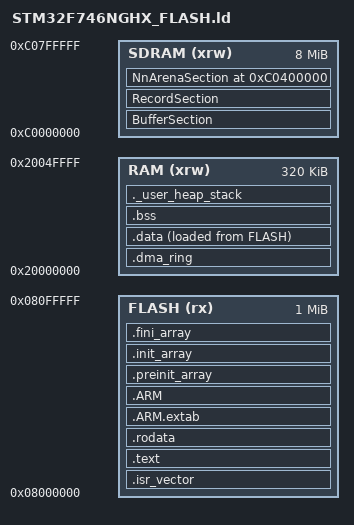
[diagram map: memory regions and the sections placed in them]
/*
******************************************************************************
**
**  File        : LinkerScript.ld
**
**  Author		: Auto-generated by STM32CubeIDE
**
**  Abstract    : Linker script for STM32F746NGHx Device from stm32f7 series
**                      1024Kbytes FLASH
**                      320Kbytes RAM
**
**                Set heap size, stack size and stack location according
**                to application requirements.
**
**                Set memory bank area and size if external memory is used.
**
**  Target      : STMicroelectronics STM32
**
**  Distribution: The file is distributed as is without any warranty
**                of any kind.
**
*****************************************************************************
** @attention
**
** <h2><center>&copy; COPYRIGHT(c) 2019 STMicroelectronics</center></h2>
**
** Redistribution and use in source and binary forms, with or without modification,
** are permitted provided that the following conditions are met:
**   1. Redistributions of source code must retain the above copyright notice,
**      this list of conditions and the following disclaimer.
**   2. Redistributions in binary form must reproduce the above copyright notice,
**      this list of conditions and the following disclaimer in the documentation
**      and/or other materials provided with the distribution.
**   3. Neither the name of STMicroelectronics nor the names of its contributors
**      may be used to endorse or promote products derived from this software
**      without specific prior written permission.
**
** THIS SOFTWARE IS PROVIDED BY THE COPYRIGHT HOLDERS AND CONTRIBUTORS "AS IS"
** AND ANY EXPRESS OR IMPLIED WARRANTIES, INCLUDING, BUT NOT LIMITED TO, THE
** IMPLIED WARRANTIES OF MERCHANTABILITY AND FITNESS FOR A PARTICULAR PURPOSE ARE
** DISCLAIMED. IN NO EVENT SHALL THE COPYRIGHT HOLDER OR CONTRIBUTORS BE LIABLE
** FOR ANY DIRECT, INDIRECT, INCIDENTAL, SPECIAL, EXEMPLARY, OR CONSEQUENTIAL
** DAMAGES (INCLUDING, BUT NOT LIMITED TO, PROCUREMENT OF SUBSTITUTE GOODS OR
** SERVICES; LOSS OF USE, DATA, OR PROFITS; OR BUSINESS INTERRUPTION) HOWEVER
** CAUSED AND ON ANY THEORY OF LIABILITY, WHETHER IN CONTRACT, STRICT LIABILITY,
** OR TORT (INCLUDING NEGLIGENCE OR OTHERWISE) ARISING IN ANY WAY OUT OF THE USE
** OF THIS SOFTWARE, EVEN IF ADVISED OF THE POSSIBILITY OF SUCH DAMAGE.
**
*****************************************************************************
*/

/* Entry Point */
ENTRY(Reset_Handler)

/* Highest address of the user mode stack */
_estack = ORIGIN(RAM) + LENGTH(RAM);	/* end of "RAM" Ram type memory */

_Min_Heap_Size = 0xa00 ;	/* required amount of heap  */
_Min_Stack_Size = 0xa00 ;	/* required amount of stack */

/* Memories definition */
MEMORY
{
  RAM     (xrw)  : ORIGIN = 0x20000000,  LENGTH = 320K
  FLASH   (rx)   : ORIGIN = 0x8000000,   LENGTH = 1024K
  SDRAM   (xrw)  : ORIGIN = 0xC0000000,  LENGTH = 8M
}

/* Sections */
SECTIONS
{
  /* The startup code into "FLASH" Rom type memory */
  .isr_vector :
  {
    . = ALIGN(4);
    KEEP(*(.isr_vector)) /* Startup code */
    . = ALIGN(4);
  } >FLASH

  /* The program code and other data into "FLASH" Rom type memory */
  .text :
  {
    . = ALIGN(4);
    *(.text)           /* .text sections (code) */
    *(.text*)          /* .text* sections (code) */
    *(.glue_7)         /* glue arm to thumb code */
    *(.glue_7t)        /* glue thumb to arm code */
    *(.eh_frame)

    KEEP (*(.init))
    KEEP (*(.fini))

    . = ALIGN(4);
    _etext = .;        /* define a global symbols at end of code */
  } >FLASH

  /* Constant data into "FLASH" Rom type memory */
  .rodata :
  {
    . = ALIGN(4);
    *(.rodata)         /* .rodata sections (constants, strings, etc.) */
    *(.rodata*)        /* .rodata* sections (constants, strings, etc.) */
    . = ALIGN(4);
  } >FLASH

  .ARM.extab   : {
    . = ALIGN(4);
    *(.ARM.extab* .gnu.linkonce.armextab.*)
    . = ALIGN(4);
  } >FLASH

  .ARM : {
    . = ALIGN(4);
    __exidx_start = .;
    *(.ARM.exidx*)
    __exidx_end = .;
    . = ALIGN(4);
  } >FLASH

  .preinit_array     :
  {
    . = ALIGN(4);
    PROVIDE_HIDDEN (__preinit_array_start = .);
    KEEP (*(.preinit_array*))
    PROVIDE_HIDDEN (__preinit_array_end = .);
    . = ALIGN(4);
  } >FLASH

  .init_array :
  {
    . = ALIGN(4);
    PROVIDE_HIDDEN (__init_array_start = .);
    KEEP (*(SORT(.init_array.*)))
    KEEP (*(.init_array*))
    PROVIDE_HIDDEN (__init_array_end = .);
    . = ALIGN(4);
  } >FLASH

  .fini_array :
  {
    . = ALIGN(4);
    PROVIDE_HIDDEN (__fini_array_start = .);
    KEEP (*(SORT(.fini_array.*)))
    KEEP (*(.fini_array*))
    PROVIDE_HIDDEN (__fini_array_end = .);
    . = ALIGN(4);
  } >FLASH

  /* Used by the startup to initialize data */
  _sidata = LOADADDR(.data);

  /* DMA ring of the event task: first thing in RAM, i.e. in the DTCM (0x20000000, 64 KB), which the core
     does not cache and the DMA reaches through the AHBS port */
  .dma_ring (NOLOAD) :
  {
    . = ALIGN(32);
    *(.dma_ring .dma_ring.*)
    . = ALIGN(32);
  } >RAM

  /* Initialized data sections into "RAM" Ram type memory */
  .data :
  {
    . = ALIGN(4);
    _sdata = .;        /* create a global symbol at data start */
    *(.data)           /* .data sections */
    *(.data*)          /* .data* sections */

    . = ALIGN(4);
    _edata = .;        /* define a global symbol at data end */

  } >RAM AT> FLASH

  /* Uninitialized data section into "RAM" Ram type memory */
  . = ALIGN(4);
  .bss :
  {
    /* This is used by the startup in order to initialize the .bss section */
    _sbss = .;         /* define a global symbol at bss start */
    __bss_start__ = _sbss;
    *(.bss)
    *(.bss*)
    *(COMMON)

    . = ALIGN(4);
    _ebss = .;         /* define a global symbol at bss end */
    __bss_end__ = _ebss;
  } >RAM

  /* User_heap_stack section, used to check that there is enough "RAM" Ram  type memory left */
  ._user_heap_stack :
  {
    . = ALIGN(8);
    PROVIDE ( end = . );
    PROVIDE ( _end = . );
    . = . + _Min_Heap_Size;
    . = . + _Min_Stack_Size;
    . = ALIGN(8);
  } >RAM

  /* Remove information from the compiler libraries */
  /DISCARD/ :
  {
    libc.a ( * )
    libm.a ( * )
    libgcc.a ( * )
  }

  .ARM.attributes 0 : { *(.ARM.attributes) }

  /* Frame buffers: lower 4 MB of SDRAM, device memory (not cached), shared with the LTDC and the DMA */
  BufferSection (NOLOAD) :
  {
    . = ALIGN(32);
    *(Display_Buffers Display_Buffers.*)
    . = ALIGN(32);
    *(Uncached_SDRAM Uncached_SDRAM.*)
    . = ALIGN(32);
  } >SDRAM

  /* Event recording buffer (tools/record.py): also not cached, so a debugger dump sees every word */
  RecordSection (NOLOAD) :
  {
    . = ALIGN(32);
    *(Record_Buffer Record_Buffer.*)
    . = ALIGN(32);
  } >SDRAM
  ASSERT(ADDR(RecordSection) + SIZEOF(RecordSection) <= 0xC0400000, "RecordSection overlaps the NN arena")

  /* Network tensors and pictures: upper 4 MB of SDRAM, a cacheable MPU region (MPU_Config() in main.c) */
  NnArenaSection 0xC0400000 (NOLOAD) :
  {
    . = ALIGN(32);
    *(NN_Arena NN_Arena.*)
    . = ALIGN(32);
  } >SDRAM
  ASSERT(ADDR(BufferSection) + SIZEOF(BufferSection) <= 0xC0400000, "BufferSection overlaps the NN arena")

}
